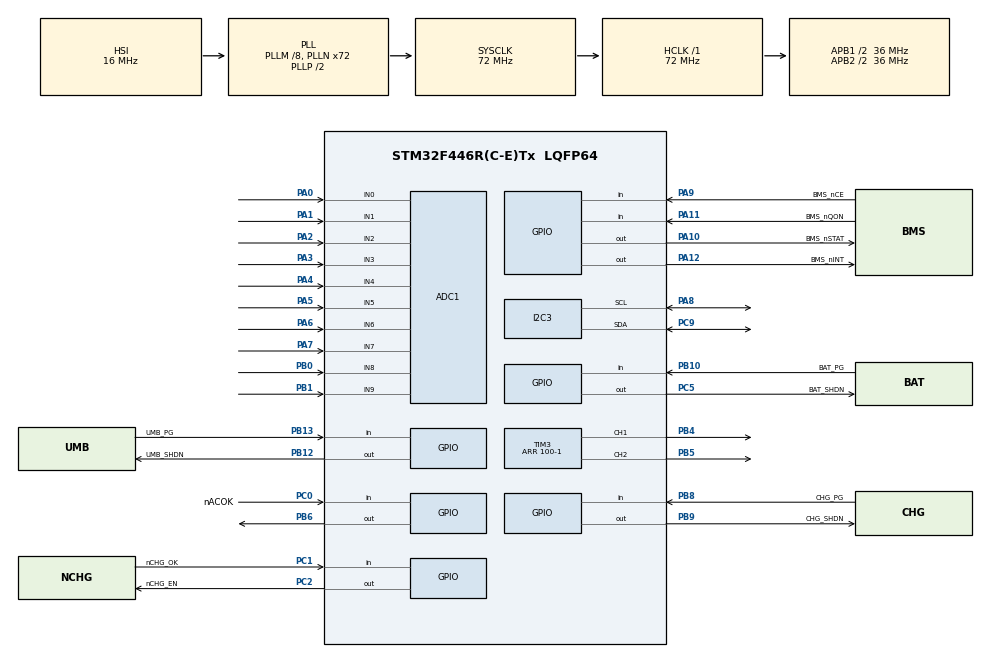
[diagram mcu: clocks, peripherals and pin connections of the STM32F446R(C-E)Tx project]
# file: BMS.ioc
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ADC1.Channel-0\#ChannelRegularConversion=ADC_CHANNEL_0
ADC1.Channel-1\#ChannelRegularConversion=ADC_CHANNEL_1
ADC1.Channel-10\#ChannelRegularConversion=ADC_CHANNEL_9
ADC1.Channel-11\#ChannelRegularConversion=ADC_CHANNEL_VREFINT
ADC1.Channel-2\#ChannelRegularConversion=ADC_CHANNEL_2
ADC1.Channel-3\#ChannelRegularConversion=ADC_CHANNEL_3
ADC1.Channel-4\#ChannelRegularConversion=ADC_CHANNEL_4
ADC1.Channel-5\#ChannelRegularConversion=ADC_CHANNEL_5
ADC1.Channel-6\#ChannelRegularConversion=ADC_CHANNEL_6
ADC1.Channel-7\#ChannelRegularConversion=ADC_CHANNEL_7
ADC1.Channel-8\#ChannelRegularConversion=ADC_CHANNEL_8
ADC1.DMAContinuousRequests=ENABLE
ADC1.EOCSelection=ADC_EOC_SEQ_CONV
ADC1.ExternalTrigConv=ADC_EXTERNALTRIGCONV_T2_TRGO
ADC1.InjNumberOfConversion=0
ADC1.NbrOfConversion=11
ADC1.NbrOfConversionFlag=1
ADC1.Rank-0\#ChannelRegularConversion=1
ADC1.Rank-1\#ChannelRegularConversion=2
ADC1.Rank-10\#ChannelRegularConversion=10
ADC1.Rank-11\#ChannelRegularConversion=11
ADC1.Rank-2\#ChannelRegularConversion=3
ADC1.Rank-3\#ChannelRegularConversion=4
ADC1.Rank-4\#ChannelRegularConversion=5
ADC1.Rank-5\#ChannelRegularConversion=6
ADC1.Rank-6\#ChannelRegularConversion=7
ADC1.Rank-7\#ChannelRegularConversion=8
ADC1.Rank-8\#ChannelRegularConversion=9
ADC1.SamplingTime-0\#ChannelRegularConversion=ADC_SAMPLETIME_112CYCLES
ADC1.SamplingTime-1\#ChannelRegularConversion=ADC_SAMPLETIME_112CYCLES
ADC1.SamplingTime-10\#ChannelRegularConversion=ADC_SAMPLETIME_112CYCLES
ADC1.SamplingTime-11\#ChannelRegularConversion=ADC_SAMPLETIME_112CYCLES
ADC1.SamplingTime-2\#ChannelRegularConversion=ADC_SAMPLETIME_112CYCLES
ADC1.SamplingTime-3\#ChannelRegularConversion=ADC_SAMPLETIME_112CYCLES
ADC1.SamplingTime-4\#ChannelRegularConversion=ADC_SAMPLETIME_112CYCLES
ADC1.SamplingTime-5\#ChannelRegularConversion=ADC_SAMPLETIME_112CYCLES
ADC1.SamplingTime-6\#ChannelRegularConversion=ADC_SAMPLETIME_112CYCLES
ADC1.SamplingTime-7\#ChannelRegularConversion=ADC_SAMPLETIME_112CYCLES
ADC1.SamplingTime-8\#ChannelRegularConversion=ADC_SAMPLETIME_112CYCLES
ADC1.ScanConvMode=ENABLE
ADC1.master=1
Dma.ADC1.0.Direction=DMA_PERIPH_TO_MEMORY
Dma.ADC1.0.FIFOMode=DMA_FIFOMODE_DISABLE
Dma.ADC1.0.Instance=DMA2_Stream0
Dma.ADC1.0.MemDataAlignment=DMA_MDATAALIGN_HALFWORD
Dma.ADC1.0.MemInc=DMA_MINC_ENABLE
Dma.ADC1.0.Mode=DMA_CIRCULAR
Dma.ADC1.0.PeriphDataAlignment=DMA_PDATAALIGN_HALFWORD
Dma.ADC1.0.PeriphInc=DMA_PINC_DISABLE
Dma.ADC1.0.Priority=DMA_PRIORITY_LOW
Dma.Request0=ADC1
I2C3.OwnAddress=0x6B
Mcu.Family=STM32F4
Mcu.Name=STM32F446R(C-E)Tx
Mcu.Package=LQFP64
NVIC.DMA2_Stream0_IRQn=true\:0\:0\:false\:false\:true\:false\:true\:true
NVIC.I2C3_ER_IRQn=true\:0\:0\:false\:false\:true\:true\:true\:true
NVIC.I2C3_EV_IRQn=true\:0\:0\:false\:false\:true\:true\:true\:true
NVIC.PriorityGroup=NVIC_PRIORITYGROUP_4
PA0-WKUP.Signal=ADCx_IN0
PA1.Signal=ADCx_IN1
PA10.GPIO_Label=BMS_nSTAT
PA10.Signal=GPIO_Output
PA11.GPIO_Label=BMS_nQON
PA11.Signal=GPIO_Input
PA12.GPIO_Label=BMS_nINT
PA12.Signal=GPIO_Output
PA2.Signal=ADCx_IN2
PA3.Signal=ADCx_IN3
PA4.Signal=ADCx_IN4
PA5.Signal=ADCx_IN5
PA6.Signal=ADCx_IN6
PA7.Signal=ADCx_IN7
PA8.Mode=I2C
PA8.Signal=I2C3_SCL
PA9.GPIO_Label=BMS_nCE
PA9.Signal=GPIO_Input
PB0.Signal=ADCx_IN8
PB1.Signal=ADCx_IN9
PB10.GPIO_Label=BAT_PG
PB10.Signal=GPIO_Input
PB12.GPIO_Label=UMB_SHDN
PB12.Signal=GPIO_Output
PB13.GPIO_Label=UMB_PG
PB13.GPIO_PuPd=GPIO_PULLUP
PB13.Signal=GPIO_Input
PB4.GPIO_Speed=GPIO_SPEED_FREQ_VERY_HIGH
PB4.Signal=S_TIM3_CH1
PB5.GPIO_Speed=GPIO_SPEED_FREQ_VERY_HIGH
PB5.Signal=S_TIM3_CH2
PB6.Signal=GPIO_Output
PB8.GPIO_Label=CHG_PG
PB8.GPIO_PuPd=GPIO_PULLUP
PB8.Signal=GPIO_Input
PB9.GPIO_Label=CHG_SHDN
PB9.Signal=GPIO_Output
PC0.GPIO_Label=nACOK
PC0.GPIO_PuPd=GPIO_PULLUP
PC0.Signal=GPIO_Input
PC1.GPIO_Label=nCHG_OK
PC1.GPIO_PuPd=GPIO_PULLUP
PC1.Signal=GPIO_Input
PC2.GPIO_Label=nCHG_EN
PC2.Signal=GPIO_Output
PC5.GPIO_Label=BAT_SHDN
PC5.Signal=GPIO_Output
PC9.Mode=I2C
PC9.Signal=I2C3_SDA
ProjectManager.HeapSize=0x200
ProjectManager.StackSize=0x400
ProjectManager.TargetToolchain=EWARM V8.50
RCC.AHBFreq_Value=72000000
RCC.APB1CLKDivider=RCC_HCLK_DIV2
RCC.APB1Freq_Value=36000000
RCC.APB1TimFreq_Value=72000000
RCC.APB2CLKDivider=RCC_HCLK_DIV2
RCC.APB2Freq_Value=36000000
RCC.APB2TimFreq_Value=72000000
RCC.CortexFreq_Value=72000000
RCC.HCLKFreq_Value=72000000
RCC.HSE_VALUE=12000000
RCC.PLLM=8
RCC.PLLN=72
RCC.SYSCLKFreq_VALUE=72000000
RCC.SYSCLKSource=RCC_SYSCLKSOURCE_PLLCLK
RCC.USBFreq_Value=72000000
RCC.VCOOutputFreq_Value=144000000
SH.ADCx_IN0.0=ADC1_IN0,IN0
SH.ADCx_IN1.0=ADC1_IN1,IN1
SH.ADCx_IN2.0=ADC1_IN2,IN2
SH.ADCx_IN3.0=ADC1_IN3,IN3
SH.ADCx_IN4.0=ADC1_IN4,IN4
SH.ADCx_IN5.0=ADC1_IN5,IN5
SH.ADCx_IN6.0=ADC1_IN6,IN6
SH.ADCx_IN7.0=ADC1_IN7,IN7
SH.ADCx_IN8.0=ADC1_IN8,IN8
SH.ADCx_IN9.0=ADC1_IN9,IN9
SH.S_TIM3_CH1.0=TIM3_CH1,PWM Generation1 CH1
SH.S_TIM3_CH2.0=TIM3_CH2,PWM Generation2 CH2
TIM2.Period=1000-1
TIM2.Prescaler=72-1
TIM2.TIM_MasterOutputTrigger=TIM_TRGO_UPDATE
TIM2.TIM_MasterSlaveMode=TIM_MASTERSLAVEMODE_DISABLE
TIM3.AutoReloadPreload=TIM_AUTORELOAD_PRELOAD_ENABLE
TIM3.Channel-PWM\ Generation1\ CH1=TIM_CHANNEL_1
TIM3.Channel-PWM\ Generation2\ CH2=TIM_CHANNEL_2
TIM3.Period=100-1
TIM3.Pulse-PWM\ Generation1\ CH1=500
VP_ADC1_Vref_Input.Mode=IN-Vrefint
VP_TIM2_VS_ClockSourceINT.Mode=Internal
VP_TIM3_VS_ClockSourceINT.Mode=Internal
board=custom

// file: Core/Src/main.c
/* USER CODE BEGIN Header */
/**
  ******************************************************************************
  * @file           : main.c
  * @brief          : Main program body
  ******************************************************************************
  * @attention
  *
  * Copyright (c) 2026 STMicroelectronics.
  * All rights reserved.
  *
  * This software is licensed under terms that can be found in the LICENSE file
  * in the root directory of this software component.
  * If no LICENSE file comes with this software, it is provided AS-IS.
  *
  ******************************************************************************
  */
/* USER CODE END Header */
#include "main.h"
#include "adc.h"
#include "dma.h"
#include "i2c.h"
#include "tim.h"
#include "gpio.h"

/* USER CODE BEGIN Includes */
#include "scheduler.h"

/* USER CODE END Includes */

void SystemClock_Config(void);

int main(void)
{

  /* MCU Configuration--------------------------------------------------------*/

  /* Reset of all peripherals, Initializes the Flash interface and the Systick. */
  HAL_Init();

  /* Configure the system clock */
  SystemClock_Config();

  /* Initialize all configured peripherals */
  MX_GPIO_Init();
  MX_DMA_Init();
  MX_I2C3_Init();
  MX_ADC1_Init();
  MX_TIM2_Init();
  MX_TIM3_Init();
  /* USER CODE BEGIN 2 */
  SCHEDULER_Init();
  ANALOG_Init();
  HAL_Delay(500);
  MPPT_Init();
  HAL_Delay(500); //Let DMA and timers bootup before powerpath
  POWERPATH_Init();
  MPPT_Init();
  TELEMETRY_Init();

  /* USER CODE END 2 */

  /* Infinite loop */
  /* USER CODE BEGIN WHILE */
  while (1)
  {
    SCHEDULER_Run();

    /* USER CODE END WHILE */

  }
}

void SystemClock_Config(void)
{
  RCC_OscInitTypeDef RCC_OscInitStruct = {0};
  RCC_ClkInitTypeDef RCC_ClkInitStruct = {0};

  /** Configure the main internal regulator output voltage
  */
  __HAL_RCC_PWR_CLK_ENABLE();
  __HAL_PWR_VOLTAGESCALING_CONFIG(PWR_REGULATOR_VOLTAGE_SCALE3);

  /** Initializes the RCC Oscillators according to the specified parameters
  * in the RCC_OscInitTypeDef structure.
  */
  RCC_OscInitStruct.OscillatorType = RCC_OSCILLATORTYPE_HSI;
  RCC_OscInitStruct.HSIState = RCC_HSI_ON;
  RCC_OscInitStruct.HSICalibrationValue = RCC_HSICALIBRATION_DEFAULT;
  RCC_OscInitStruct.PLL.PLLState = RCC_PLL_ON;
  RCC_OscInitStruct.PLL.PLLSource = RCC_PLLSOURCE_HSI;
  RCC_OscInitStruct.PLL.PLLM = 8;
  RCC_OscInitStruct.PLL.PLLN = 72;
  RCC_OscInitStruct.PLL.PLLP = RCC_PLLP_DIV2;
  RCC_OscInitStruct.PLL.PLLQ = 2;
  RCC_OscInitStruct.PLL.PLLR = 2;
  if (HAL_RCC_OscConfig(&RCC_OscInitStruct) != HAL_OK)
  {
    Error_Handler();
  }

  /** Initializes the CPU, AHB and APB buses clocks
  */
  RCC_ClkInitStruct.ClockType = RCC_CLOCKTYPE_HCLK|RCC_CLOCKTYPE_SYSCLK
                              |RCC_CLOCKTYPE_PCLK1|RCC_CLOCKTYPE_PCLK2;
  RCC_ClkInitStruct.SYSCLKSource = RCC_SYSCLKSOURCE_PLLCLK;
  RCC_ClkInitStruct.AHBCLKDivider = RCC_SYSCLK_DIV1;
  RCC_ClkInitStruct.APB1CLKDivider = RCC_HCLK_DIV2;
  RCC_ClkInitStruct.APB2CLKDivider = RCC_HCLK_DIV2;

  if (HAL_RCC_ClockConfig(&RCC_ClkInitStruct, FLASH_LATENCY_2) != HAL_OK)
  {
    Error_Handler();
  }
}

void Error_Handler(void)
{
  __disable_irq();
  while (1)
  {
  }
}
